# ATxmega128A1 register map
Vendor: Atmel; File version: 1.0
CPU: other r0p0, little endian, no MPU, no FPU, 4 interrupt priority bits
Registers are 8-bit, read-write, reset 0x0 unless marked. A register's access mark holds for its fields unless they carry their own. Offsets are from the block's base; [hi:lo] are bit positions; {n}, {i} and the like mark numbered series; 'fields as' and 'values as' point back to an identical list.

## PORT_CFG — Port Configuration
Base 0x000000B0
0x00 MPCMASK — Multi-pin Configuration Mask
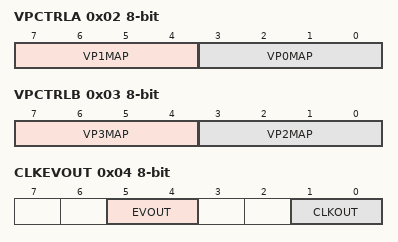
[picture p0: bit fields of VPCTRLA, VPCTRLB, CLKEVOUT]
0x02 VPCTRLA — Virtual Port Control Register A
  [7:4] VP1MAP — Virtual Port 1 Mapping
    0=PORTA (Mapped To PORTA); 1=PORTB (Mapped To PORTB); 2=PORTC (Mapped To PORTC); 3=PORTD (Mapped To PORTD); 4=PORTE (Mapped To PORTE); 5=PORTF (Mapped To PORTF); 6=PORTG (Mapped To PORTG); 7=PORTH (Mapped To PORTH); 8=PORTJ (Mapped To PORTJ); 9=PORTK (Mapped To PORTK); 10=PORTL (Mapped To PORTL); 11=PORTM (Mapped To PORTM); 12=PORTN (Mapped To PORTN); 13=PORTP (Mapped To PORTP); 14=PORTQ (Mapped To PORTQ); 15=PORTR (Mapped To PORTR)
  [3:0] VP0MAP — Virtual Port 0 Mapping
    values as VP1MAP
0x03 VPCTRLB — Virtual Port Control Register B
  [7:4] VP3MAP — Virtual Port 3 Mapping
    values as VPCTRLA.VP1MAP
  [3:0] VP2MAP — Virtual Port 2 Mapping
    values as VPCTRLA.VP1MAP
0x04 CLKEVOUT — Clock and Event Out Register
  [5:4] EVOUT — Event Output Port
    0=OFF (Event Output Disabled); 1=PC7 (Event Channel 7 Output on Port C pin 7); 2=PD7 (Event Channel 7 Output on Port D pin 7); 3=PE7 (Event Channel 7 Output on Port E pin 7)
  [1:0] CLKOUT — Clock Output Port
    0=OFF (Clock Output Disabled); 1=PC7 (Clock Output on Port C pin 7); 2=PD7 (Clock Output on Port D pin 7); 3=PE7 (Clock Output on Port E pin 7)

## PR — Clock System
Base 0x00000070
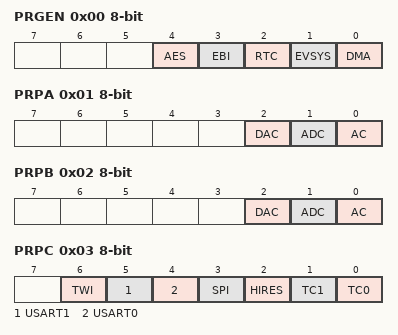
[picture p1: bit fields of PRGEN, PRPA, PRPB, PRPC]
0x00 PRGEN — General Power Reduction
  [4] AES
  [3] EBI — External Bus Interface
  [2] RTC — Real-time Counter
  [1] EVSYS — Event System
  [0] DMA — DMA-Controller
0x01 PRPA — Power Reduction Port A
  [2] DAC — Port A DAC
  [1] ADC — Port A ADC
  [0] AC — Port A Analog Comparator
0x02 PRPB — Power Reduction Port B
  [2] DAC — Port B DAC
  [1] ADC — Port B ADC
  [0] AC — Port B Analog Comparator
0x03 PRPC — Power Reduction Port C
  [6] TWI — Port C Two-wire Interface
  [5] USART1 — Port C USART1
  [4] USART0 — Port C USART0
  [3] SPI — Port C SPI
  [2] HIRES — Port C AWEX
  [1] TC1 — Port C Timer/Counter1
  [0] TC0 — Port C Timer/Counter0
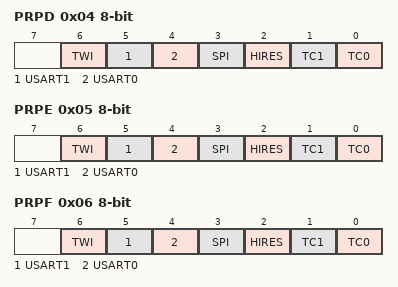
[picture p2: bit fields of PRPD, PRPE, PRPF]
0x04 PRPD — Power Reduction Port D
  [6] TWI — Port D Two-wire Interface
  [5] USART1 — Port D USART1
  [4] USART0 — Port D USART0
  [3] SPI — Port D SPI
  [2] HIRES — Port D AWEX
  [1] TC1 — Port D Timer/Counter1
  [0] TC0 — Port D Timer/Counter0
0x05 PRPE — Power Reduction Port E
  [6] TWI — Port E Two-wire Interface
  [5] USART1 — Port E USART1
  [4] USART0 — Port E USART0
  [3] SPI — Port E SPI
  [2] HIRES — Port E AWEX
  [1] TC1 — Port E Timer/Counter1
  [0] TC0 — Port E Timer/Counter0
0x06 PRPF — Power Reduction Port F
  [6] TWI — Port F Two-wire Interface
  [5] USART1 — Port F USART1
  [4] USART0 — Port F USART0
  [3] SPI — Port F SPI
  [2] HIRES — Port F AWEX
  [1] TC1 — Port F Timer/Counter1
  [0] TC0 — Port F Timer/Counter0

## PROD_SIGNATURES — Non Volatile Memory Controller
Base 0x00000000
0x00 RCOSC2M — RCOSC 2MHz Calibration Value
0x02 RCOSC32K — RCOSC 32kHz Calibration Value
0x03 RCOSC32M — RCOSC 32MHz Calibration Value
{0x8+i} LOTNUM{i} (i=0..5) — Lot Number Byte {i}, ASCII
0x10 WAFNUM — Wafer Number
0x12 COORDX0 — Wafer Coordinate X Byte 0
0x13 COORDX1 — Wafer Coordinate X Byte 1
0x14 COORDY0 — Wafer Coordinate Y Byte 0
0x15 COORDY1 — Wafer Coordinate Y Byte 1
0x20 ADCACAL0 — ADCA Calibration Byte 0
0x21 ADCACAL1 — ADCA Calibration Byte 1
0x24 ADCBCAL0 — ADCB Calibration Byte 0
0x25 ADCBCAL1 — ADCB Calibration Byte 1
0x2E TEMPSENSE0 — Temperature Sensor Calibration Byte 0
0x2F TEMPSENSE1 — Temperature Sensor Calibration Byte 0
0x30 DACAOFFCAL — DACA Calibration Byte 0
0x31 DACAGAINCAL — DACA Calibration Byte 1
0x32 DACBOFFCAL — DACB Calibration Byte 0
0x33 DACBGAINCAL — DACB Calibration Byte 1
